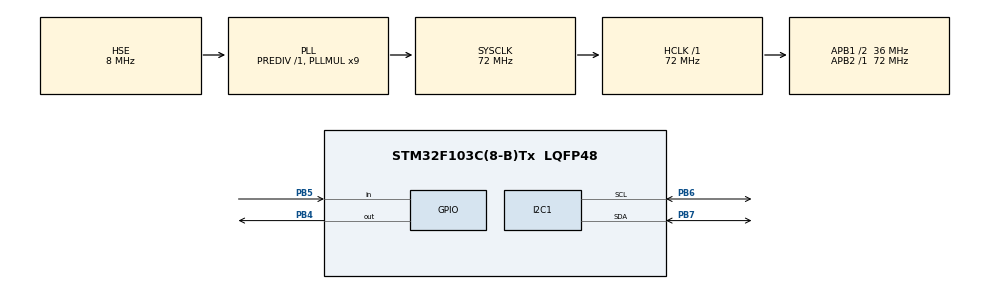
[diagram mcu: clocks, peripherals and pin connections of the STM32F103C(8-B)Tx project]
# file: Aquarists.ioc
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Mcu.Family=STM32F1
Mcu.Name=STM32F103C(8-B)Tx
Mcu.Package=LQFP48
NVIC.PriorityGroup=NVIC_PRIORITYGROUP_4
PA13.Mode=Serial_Wire
PA13.Signal=SYS_JTMS-SWDIO
PA14.Mode=Serial_Wire
PA14.Signal=SYS_JTCK-SWCLK
PB4.GPIO_Speed=GPIO_SPEED_FREQ_HIGH
PB4.Signal=GPIO_Output
PB5.GPIO_PuPd=GPIO_PULLUP
PB5.Signal=GPIO_Input
PB6.Mode=I2C
PB6.Signal=I2C1_SCL
PB7.Mode=I2C
PB7.Signal=I2C1_SDA
PD0-OSC_IN.Mode=HSE-External-Oscillator
PD0-OSC_IN.Signal=RCC_OSC_IN
PD1-OSC_OUT.Mode=HSE-External-Oscillator
PD1-OSC_OUT.Signal=RCC_OSC_OUT
ProjectManager.HeapSize=0x200
ProjectManager.StackSize=0x400
ProjectManager.TargetToolchain=MDK-ARM V5.32
RCC.AHBFreq_Value=72000000
RCC.APB1CLKDivider=RCC_HCLK_DIV2
RCC.APB1Freq_Value=36000000
RCC.APB1TimFreq_Value=72000000
RCC.APB2Freq_Value=72000000
RCC.APB2TimFreq_Value=72000000
RCC.HCLKFreq_Value=72000000
RCC.PLLMUL=RCC_PLL_MUL9
RCC.PLLSourceVirtual=RCC_PLLSOURCE_HSE
RCC.SYSCLKFreq_VALUE=72000000
RCC.SYSCLKSource=RCC_SYSCLKSOURCE_PLLCLK
RCC.USBFreq_Value=72000000
board=custom

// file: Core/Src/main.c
/* USER CODE BEGIN Header */
/**
  ******************************************************************************
  * @file           : main.c
  * @brief          : Main program body
  ******************************************************************************
  * @attention
  *
  * Copyright (c) 2023 STMicroelectronics.
  * All rights reserved.
  *
  * This software is licensed under terms that can be found in the LICENSE file
  * in the root directory of this software component.
  * If no LICENSE file comes with this software, it is provided AS-IS.
  *
  ******************************************************************************
  */
/* USER CODE END Header */
#include "main.h"

/* USER CODE BEGIN Includes */
#include "stdio.h"
#include "liquidcrystal_i2c.h"
/* USER CODE END Includes */

I2C_HandleTypeDef hi2c1;

void SystemClock_Config(void);
static void MX_GPIO_Init(void);
static void MX_I2C1_Init(void);

/* USER CODE BEGIN 0 */
/**I2C1 GPIO Configuration
    PB6     ------> I2C1_SCL
    PB7     ------> I2C1_SDA
    */

/* USER CODE END 0 */

int main(void)
{
	uint8_t count = 0;
	char str[10];
  /* USER CODE BEGIN 1 */
	uint8_t special1[8] = {
				0b01000,
        0b00100,
        0b01010,
        0b01010,
        0b10001,
        0b10001,
        0b10001,
        0b01110
};
	uint8_t special2[8] = {
        0b00000,
        0b11001,
        0b11011,
        0b00110,
        0b01100,
        0b11011,
        0b10011,
        0b00000
};

uint8_t special3[8] = {
        0b11000,
        0b11000,
        0b00110,
        0b01001,
        0b01000,
        0b01001,
        0b00110,
        0b00000
};
uint8_t special4[8] = {
        0b01010,
        0b10101,
        0b10101,
        0b10001,
        0b10001,
        0b01010,
        0b00100,
        0b00000
};
  /* USER CODE END 1 */

  /* MCU Configuration--------------------------------------------------------*/

  /* Reset of all peripherals, Initializes the Flash interface and the Systick. */
  HAL_Init();

  /* Configure the system clock */
  SystemClock_Config();

  /* Initialize all configured peripherals */
  MX_GPIO_Init();
  MX_I2C1_Init();
  /* USER CODE BEGIN 2 */
	LCD_Init(2);
	LCD_Clear();
	LCD_Backlight();
	LCD_Cursor();
	LCD_SetCursor(0,0);
	sprintf(str,"%d",count);
	LCD_PrintStr(str);

	LCD_LoadCustomCharacter(0,special1);
	LCD_LoadCustomCharacter(1,special2);
	LCD_LoadCustomCharacter(2,special3);
	LCD_LoadCustomCharacter(3,special4);
	LCD_SetCursor(0,1);
	LCD_PrintSpecialChar(0);
	LCD_SetCursor(1,1);
	LCD_PrintSpecialChar(1);
	LCD_SetCursor(2,1);
	LCD_PrintSpecialChar(2);
	LCD_SetCursor(3,1);
	LCD_PrintSpecialChar(3);
	LCD_SetCursor(0,0);
  /* USER CODE END 2 */

  /* Infinite loop */
  while (1)
  {
		if(GPIO_PIN_RESET == HAL_GPIO_ReadPin(GPIOB,GPIO_PIN_5))
		{
			while(GPIO_PIN_RESET == HAL_GPIO_ReadPin(GPIOB,GPIO_PIN_5));
			LCD_SetCursor(0,0);
			sprintf(str,"%d",++count);
			LCD_PrintStr(str);
			HAL_GPIO_TogglePin(GPIOB,GPIO_PIN_4);
		}
		if(GPIO_PIN_RESET == HAL_GPIO_ReadPin(GPIOB,GPIO_PIN_8))
		{
			while(GPIO_PIN_RESET == HAL_GPIO_ReadPin(GPIOB,GPIO_PIN_8));
			LCD_SetCursor(0,0);
			sprintf(str,"%d",--count);
			LCD_PrintStr(str);
			HAL_GPIO_TogglePin(GPIOB,GPIO_PIN_4);
		}
  }
}

void SystemClock_Config(void)
{
  RCC_OscInitTypeDef RCC_OscInitStruct = {0};
  RCC_ClkInitTypeDef RCC_ClkInitStruct = {0};

  /** Initializes the RCC Oscillators according to the specified parameters
  * in the RCC_OscInitTypeDef structure.
  */
  RCC_OscInitStruct.OscillatorType = RCC_OSCILLATORTYPE_HSE;
  RCC_OscInitStruct.HSEState = RCC_HSE_ON;
  RCC_OscInitStruct.HSEPredivValue = RCC_HSE_PREDIV_DIV1;
  RCC_OscInitStruct.HSIState = RCC_HSI_ON;
  RCC_OscInitStruct.PLL.PLLState = RCC_PLL_ON;
  RCC_OscInitStruct.PLL.PLLSource = RCC_PLLSOURCE_HSE;
  RCC_OscInitStruct.PLL.PLLMUL = RCC_PLL_MUL9;
  if (HAL_RCC_OscConfig(&RCC_OscInitStruct) != HAL_OK)
  {
    Error_Handler();
  }

  /** Initializes the CPU, AHB and APB buses clocks
  */
  RCC_ClkInitStruct.ClockType = RCC_CLOCKTYPE_HCLK|RCC_CLOCKTYPE_SYSCLK
                              |RCC_CLOCKTYPE_PCLK1|RCC_CLOCKTYPE_PCLK2;
  RCC_ClkInitStruct.SYSCLKSource = RCC_SYSCLKSOURCE_PLLCLK;
  RCC_ClkInitStruct.AHBCLKDivider = RCC_SYSCLK_DIV1;
  RCC_ClkInitStruct.APB1CLKDivider = RCC_HCLK_DIV2;
  RCC_ClkInitStruct.APB2CLKDivider = RCC_HCLK_DIV1;

  if (HAL_RCC_ClockConfig(&RCC_ClkInitStruct, FLASH_LATENCY_2) != HAL_OK)
  {
    Error_Handler();
  }
}

static void MX_I2C1_Init(void)
{

  hi2c1.Instance = I2C1;
  hi2c1.Init.ClockSpeed = 100000;
  hi2c1.Init.DutyCycle = I2C_DUTYCYCLE_2;
  hi2c1.Init.OwnAddress1 = 0;
  hi2c1.Init.AddressingMode = I2C_ADDRESSINGMODE_7BIT;
  hi2c1.Init.DualAddressMode = I2C_DUALADDRESS_DISABLE;
  hi2c1.Init.OwnAddress2 = 0;
  hi2c1.Init.GeneralCallMode = I2C_GENERALCALL_DISABLE;
  hi2c1.Init.NoStretchMode = I2C_NOSTRETCH_DISABLE;
  if (HAL_I2C_Init(&hi2c1) != HAL_OK)
  {
    Error_Handler();
  }

}

static void MX_GPIO_Init(void)
{
  GPIO_InitTypeDef GPIO_InitStruct = {0};

  /* GPIO Ports Clock Enable */
  __HAL_RCC_GPIOD_CLK_ENABLE();
  __HAL_RCC_GPIOA_CLK_ENABLE();
  __HAL_RCC_GPIOB_CLK_ENABLE();

  /*Configure GPIO pin Output Level */
  HAL_GPIO_WritePin(GPIOB, GPIO_PIN_4, GPIO_PIN_RESET);

  /*Configure GPIO pin : PB4 */
  GPIO_InitStruct.Pin = GPIO_PIN_4;
  GPIO_InitStruct.Mode = GPIO_MODE_OUTPUT_PP;
  GPIO_InitStruct.Pull = GPIO_NOPULL;
  GPIO_InitStruct.Speed = GPIO_SPEED_FREQ_HIGH;
  HAL_GPIO_Init(GPIOB, &GPIO_InitStruct);

  /*Configure GPIO pin : PB5 */
  GPIO_InitStruct.Pin = GPIO_PIN_5;
  GPIO_InitStruct.Mode = GPIO_MODE_INPUT;
  GPIO_InitStruct.Pull = GPIO_PULLUP;
  HAL_GPIO_Init(GPIOB, &GPIO_InitStruct);

	/*Configure GPIO pin : PB8 */
  GPIO_InitStruct.Pin = GPIO_PIN_8;
  GPIO_InitStruct.Mode = GPIO_MODE_INPUT;
  GPIO_InitStruct.Pull = GPIO_PULLUP;
  HAL_GPIO_Init(GPIOB, &GPIO_InitStruct);

}

void Error_Handler(void)
{
  __disable_irq();
  while (1)
  {
  }
}
